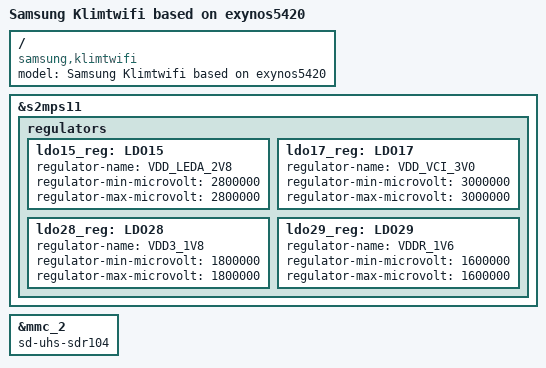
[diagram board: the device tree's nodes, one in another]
// SPDX-License-Identifier: GPL-2.0
/*
 * Samsung's Exynos5420 Klimtwifi board device tree source
 *
 * Copyright (c) 2012-2013 Samsung Electronics Co., Ltd.
 *		http://www.samsung.com
 * Copyright (c) 2022 Henrik Grimler
 */

/dts-v1/;
#include "exynos5420-galaxy-tab-common.dtsi"

/ {
	model = "Samsung Klimtwifi based on exynos5420";
	compatible = "samsung,klimtwifi", "samsung,exynos5420", \
		     "samsung,exynos5";
};

&s2mps11 {
	regulators {
		ldo15_reg: LDO15 {
			regulator-name = "VDD_LEDA_2V8";
			regulator-min-microvolt = <2800000>;
			regulator-max-microvolt = <2800000>;
		};

		ldo17_reg: LDO17 {
			regulator-name = "VDD_VCI_3V0";
			regulator-min-microvolt = <3000000>;
			regulator-max-microvolt = <3000000>;
		};

		ldo28_reg: LDO28 {
			regulator-name = "VDD3_1V8";
			regulator-min-microvolt = <1800000>;
			regulator-max-microvolt = <1800000>;
		};

		ldo29_reg: LDO29 {
			regulator-name = "VDDR_1V6";
			regulator-min-microvolt = <1600000>;
			regulator-max-microvolt = <1600000>;
		};
	};
};

&mmc_2 {
	sd-uhs-sdr104;
};
